# A31R71x register map
Vendor: VENDOR ABOV Semiconductor Co., Ltd.; Series: A31R71x; File version: 1.0
ARM 32-bit Cortex-M0+ Microcontroller based device, CPU clock up to 40MHz, etc.
CPU: CM0+ r0p1, little endian, no MPU, no FPU, VTOR, 2 interrupt priority bits
Registers are 32-bit, read-write, reset 0x0 unless marked. A register's access mark holds for its fields unless they carry their own. Offsets are from the block's base; lines under a group give offsets from that group; [hi:lo] are bit positions; {n}, {i} and the like mark numbered series; 'fields as' and 'values as' point back to an identical list; <NAME> marks a mode.

## Memory map
0x1FFFF000 COA0 size 0x100 — Configuration Option Area Page 0: System Related Trimming Value
0x1FFFF200 COA1 size 0x100 — Configuration Option Area Page 1: User Option
0x1FFFF400 COA2 size 0x100 — Configuration Option Area Page 2: User Data Area 0
0x1FFFF600 COA3 size 0x100 — Configuration Option Area Page 3: User Data Area 1
0x30000000 PA size 0x100 — Port Control Unit & GPIO Port A
0x30000100 PB size 0x100 — Port Control Unit & GPIO Port B
0x30000200 PC size 0x100 — Port Control Unit & GPIO Port C
0x30000300 PD size 0x100 — Port Control Unit & GPIO Port D
0x30000400 PE size 0x100 — Port Control Unit & GPIO Port E
0x30000500 PF size 0x100 — Port Control Unit & GPIO Port F
0x30001000 CRC size 0x100 — Cyclic Redundancy Check and Checksum
0x40001000 INTC size 0x500 — Interrupt Controller
0x40001800 SCUCG size 0x100 — System Control Unit: Clock Generation
0x40001A00 WDT size 0x100 — Watch-Dog Timer
0x40001B00 FMC size 0x200 — Flash Memory Controller
0x40002000 WT size 0x100 — Watch Timer
0x40002100 TIMER10 size 0x100 — Timer/Counter 10
0x40002200 TIMER11 size 0x100 — Timer/Counter 11
0x40002300 TIMER12 size 0x100 — Timer/Counter 12
0x40002500 TIMER20 size 0x100 — Timer/Counter 20
0x40002600 TIMER21 size 0x100 — Timer/Counter 21
0x40002700 TIMER13 size 0x100 — Timer/Counter 13
0x40002800 TIMER14 size 0x100 — Timer/Counter 14
0x40002900 TIMER15 size 0x100 — Timer/Counter 15
0x40003000 ADC size 0x100 — 12 Bit A/D Converter
0x40003800 USART10 size 0x100 — USART 10 (USART + SPI)
0x40003900 USART11 size 0x100 — USART 11 (USART + SPI)
0x40004100 UART1 size 0x100
0x40004900 I2C1 size 0x100
0x40005000 LCD size 0x100 — LCD Driver
0x40005100 SCULV size 0x100 — System Control Unit: LVI and LVR
0x4000F000 SCUCC size 0x100 — System Control Unit: Chip Configuration
0x50000000 Pn size 0x100 — Port Control Unit & GPIO Port n
0x51000000 TIMER1n size 0x100 — Timer/Counter 1n
0x52000000 TIMER2n size 0x100 — Timer/Counter 2n
0x54000000 USART1n size 0x100 — USART 1n (USART + SPI)
0x55000000 UARTn size 0x100
0x56000000 I2Cn size 0x100

## Interrupts
0 LVI (SCULV) — LVI Interrupt
1 WUT (SCUCC) — WUT Interrupt
2 WDT — WDT Interrupt
3 EINT0 (INTC) — EINT0 Interrupt
4 EINT1 (INTC) — EINT1 Interrupt
5 EINT2 (INTC) — EINT2 Interrupt
6 EINT3 (INTC) — EINT3 Interrupt
7 TIMER10 — TIMER10 Interrupt
8 TIMER11 — TIMER11 Interrupt
9 TIMER12 — TIMER12 Interrupt
11 USART10 — USART10 Interrupt
12 WT — WT Interrupt
14 I2C1 — I2C1 Interrupt
15 TIMER20 — TIMER20 Interrupt
16 TIMER21 — TIMER21 Interrupt
17 USART11 — USART11 Interrupt
18 ADC — ADC Interrupt
20 UART1 — UART1 Interrupt
21 TIMER13 — TIMER13 Interrupt
22 TIMER14 — TIMER14 Interrupt
23 TIMER15 — TIMER15 Interrupt

## SCULV — System Control Unit: LVI and LVR
Base 0x40005100
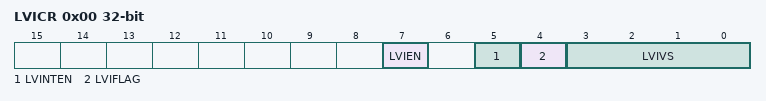
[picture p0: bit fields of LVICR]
0x00 LVICR — Low Voltage Indicator Control Register
  [7] LVIEN — LVI Enable
    0=Disable low voltage indicator; 1=Enable low voltage indicator
  [5] LVINTEN — LVI Interrupt Enable
    0=Disable low voltage indicator interrupt; 1=Enable low voltage indicator interrupt
  [4] LVIFLAG — LVI Interrupt Flag
    0=No request occurred; 1=Request occurred
  [3:0] LVIVS — LVI Voltage Selection
    3=DNW3 (Do not write.); 4=2p00V (2.00V); 5=2p13V (2.13V); 6=2p28V (2.28V); 7=2p46V (2.46V); 8=2p67V (2.67V); 9=3p04V (3.04V); 10=3p20V (3.20V); 11=3p55V (3.55V); 12=3p75V (3.75V); 13=3p99V (3.99V); 14=4p25V (4.25V); 15=4p55V (4.55V)
0x04 LVRCR — Low Voltage Reset Control Register
  [7:0] LVREN — LVR Enable
    85=Disable low voltage reset. (0x55); 0=Enable low voltage reset

## Licence text in the file
ARM Limited (ARM) is supplying this software for use with Cortex-M processor based microcontroller, but can be equally used for other suitable processor architectures. This file can be freely distributed. Modifications to this file shall be clearly marked. . THIS SOFTWARE IS PROVIDED "AS IS". NO WARRANTIES, WHETHER EXPRESS, IMPLIED. OR STATUTORY, INCLUDING, BUT NOT LIMITED TO, IMPLIED WARRANTIES OF. MERCHANTABILITY AND FITNESS FOR A PARTICULAR PURPOSE APPLY TO THIS SOFTWARE. ARM SHALL NOT, IN ANY CIRCUMSTANCES, BE LIABLE FOR SPECIAL, INCIDENTAL, OR. CONSEQUENTIAL DAMAGES, FOR ANY REASON WHATSOEVER.

## Notices in the file
Copyright (C) 2012 ARM Limited. All rights reserved.
Purpose: System Viewer Description (SVD) Example (Schema Version 1.1)
This is a description of a none-existent and incomplete device
for demonstration purposes only.
Redistribution and use in source and binary forms, with or without
modification, are permitted provided that the following conditions are met:
- Redistributions of source code must retain the above copyright
notice, this list of conditions and the following disclaimer.
- Redistributions in binary form must reproduce the above copyright
notice, this list of conditions and the following disclaimer in the
documentation and/or other materials provided with the distribution.
- Neither the name of ARM nor the names of its contributors may be used
to endorse or promote products derived from this software without
specific prior written permission.
THIS SOFTWARE IS PROVIDED BY THE COPYRIGHT HOLDERS AND CONTRIBUTORS "AS IS"
AND ANY EXPRESS OR IMPLIED WARRANTIES, INCLUDING, BUT NOT LIMITED TO, THE
ARE DISCLAIMED. IN NO EVENT SHALL COPYRIGHT HOLDERS AND CONTRIBUTORS BE
LIABLE FOR ANY DIRECT, INDIRECT, INCIDENTAL, SPECIAL, EXEMPLARY, OR
CONSEQUENTIAL DAMAGES (INCLUDING, BUT NOT LIMITED TO, PROCUREMENT OF
SUBSTITUTE GOODS OR SERVICES; LOSS OF USE, DATA, OR PROFITS; OR BUSINESS
INTERRUPTION) HOWEVER CAUSED AND ON ANY THEORY OF LIABILITY, WHETHER IN
CONTRACT, STRICT LIABILITY, OR TORT (INCLUDING NEGLIGENCE OR OTHERWISE)
ARISING IN ANY WAY OUT OF THE USE OF THIS SOFTWARE, EVEN IF ADVISED OF THE
POSSIBILITY OF SUCH DAMAGE.
